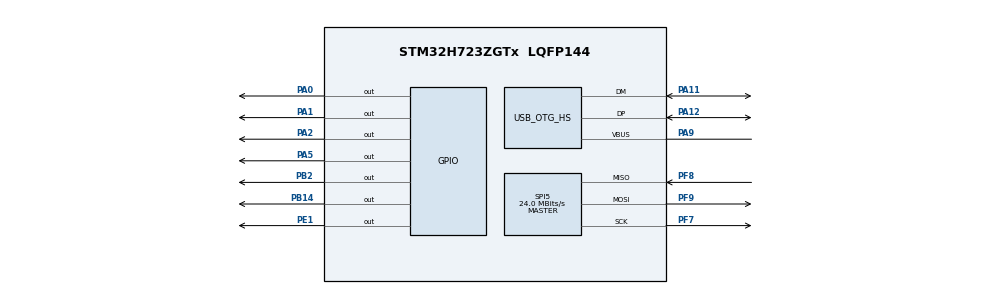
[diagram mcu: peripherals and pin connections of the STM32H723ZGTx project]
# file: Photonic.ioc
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CORTEX_M7.default_mode_Activation=1
Mcu.Family=STM32H7
Mcu.Name=STM32H723ZGTx
Mcu.Package=LQFP144
NVIC.OTG_HS_IRQn=true\:0\:0\:false\:false\:true\:true\:true\:true
NVIC.PriorityGroup=NVIC_PRIORITYGROUP_4
PA0.Signal=GPIO_Output
PA1.Signal=GPIO_Output
PA11.Mode=Device_Only_FS
PA11.Signal=USB_OTG_HS_DM
PA12.Mode=Device_Only_FS
PA12.Signal=USB_OTG_HS_DP
PA13(JTMS/SWDIO).Mode=Serial_Wire
PA13(JTMS/SWDIO).Signal=DEBUG_JTMS-SWDIO
PA14(JTCK/SWCLK).Mode=Serial_Wire
PA14(JTCK/SWCLK).Signal=DEBUG_JTCK-SWCLK
PA2.Signal=GPIO_Output
PA5.Signal=GPIO_Output
PA9.Mode=Activate_VBUS_FS
PA9.Signal=USB_OTG_HS_VBUS
PB14.Signal=GPIO_Output
PB2.Signal=GPIO_Output
PE1.Signal=GPIO_Output
PF7.Mode=Full_Duplex_Master
PF7.Signal=SPI5_SCK
PF8.Mode=Full_Duplex_Master
PF8.Signal=SPI5_MISO
PF9.Mode=Full_Duplex_Master
PF9.Signal=SPI5_MOSI
PH0-OSC_IN.Mode=HSE-External-Clock-Source
PH0-OSC_IN.Signal=RCC_OSC_IN
ProjectManager.HeapSize=0x200
ProjectManager.StackSize=0x400
ProjectManager.TargetToolchain=STM32CubeIDE
RCC.ADCFreq_Value=120000000
RCC.APB1Freq_Value=48000000
RCC.APB2Freq_Value=48000000
RCC.APB3Freq_Value=48000000
RCC.APB4Freq_Value=48000000
RCC.CortexFreq_Value=48000000
RCC.DIVM1=5
RCC.DIVN1=34
RCC.DIVN2=120
RCC.DIVN3=140
RCC.DIVP1=1
RCC.DIVQ1=8
RCC.DIVQ2=3
RCC.DIVQ3=1
RCC.HCLKFreq_Value=48000000
RCC.HSE_VALUE=48000000
RCC.PLLFRACN=3072
RCC.PWR_Regulator_Voltage_Scale=PWR_REGULATOR_VOLTAGE_SCALE3
RCC.SYSCLKFreq_VALUE=48000000
RCC.SYSCLKSource=RCC_SYSCLKSOURCE_HSE
RCC.Spi45ClockSelection=RCC_SPI45CLKSOURCE_HSE
RCC.USBCLockSelection=RCC_USBCLKSOURCE_HSI48
RCC.USBFreq_Value=48000000
SPI5.CLKPhase=SPI_PHASE_2EDGE
SPI5.CalculateBaudRate=24.0 MBits/s
SPI5.DataSize=SPI_DATASIZE_8BIT
SPI5.Direction=SPI_DIRECTION_2LINES
SPI5.Mode=SPI_MODE_MASTER
SPI5.VirtualType=VM_MASTER
TIM1.Prescaler=137
USB_DEVICE.CLASS_NAME_HS=CDC
USB_DEVICE.VirtualMode=Cdc
USB_DEVICE.VirtualModeHS=Cdc_HS
USB_OTG_HS.VirtualMode-Device_Only_FS=Device_Only_FS
VP_MEMORYMAP_VS_MEMORYMAP.Mode=CurAppReg
VP_TIM1_VS_ClockSourceINT.Mode=Internal
VP_USB_DEVICE_VS_USB_DEVICE_CDC_HS.Mode=CDC_HS
board=custom

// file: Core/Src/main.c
/* USER CODE BEGIN Header */
/**
  ******************************************************************************
  * @file           : main.c
  * @brief          : Main program body
  ******************************************************************************
  * @attention
  *
  * Copyright (c) 2025 STMicroelectronics.
  * All rights reserved.
  *
  * This software is licensed under terms that can be found in the LICENSE file
  * in the root directory of this software component.
  * If no LICENSE file comes with this software, it is provided AS-IS.
  *
  ******************************************************************************
  */
/* USER CODE END Header */
#include "main.h"
#include "usb_device.h"

/* USER CODE BEGIN PTD */
#define channel_0 8
/* USER CODE END PTD */

SPI_HandleTypeDef hspi5;

TIM_HandleTypeDef htim1;

void SystemClock_Config(void);
static void MPU_Config(void);
static void MX_GPIO_Init(void);
static void MX_SPI5_Init(void);
static void MX_TIM1_Init(void);
/* USER CODE BEGIN PFP */
uint8_t test;
/* USER CODE END PFP */

int main(void)
{

  /* MPU Configuration--------------------------------------------------------*/
  MPU_Config();

  /* MCU Configuration--------------------------------------------------------*/

  /* Reset of all peripherals, Initializes the Flash interface and the Systick. */
  HAL_Init();

  /* Configure the system clock */
  SystemClock_Config();

  /* Initialize all configured peripherals */
  MX_GPIO_Init();
  MX_SPI5_Init();
  MX_TIM1_Init();
  MX_USB_DEVICE_Init();
  /* USER CODE BEGIN 2 */
  spi_init_24bit();

  /* USER CODE END 2 */

  /* Infinite loop */
  /* USER CODE BEGIN WHILE */
 // HAL_TIM_Base_Start(&htim1); // Start TIM1

  // Read the actual PWR register to see current VOS mode

//uint32_t voltage_uv = 4563123;

//uint16_t voltage_dac = 0xFFFF;

//write_to_dac(3, 10, voltage_dac);
//uint16_t voltage_read = read_dac(3, 10);

//write_to_dac(3, 9, 0x8F32);
//uint16_t voltage_read_0 = read_dac(3, 9);
  //uint8_t voltage[3] = {0x0, 0x01, 0x00};

  GPIOA->BSRR = GPIO_PIN_0;          // set high
  GPIOA->BSRR = GPIO_PIN_1;          // set high
  GPIOA->BSRR = GPIO_PIN_2;          // set high

/*
  uint8_t ref[3] = {0x03, 0x01, 0x00};
  GPIOA->BSRR = GPIO_PIN_0 << 16U;   // set low

  HAL_SPI_Transmit(&hspi5, ref, 3, HAL_MAX_DELAY);
  GPIOA->BSRR = GPIO_PIN_0;

  GPIOA->BSRR = GPIO_PIN_1 << 16U;   // set low

  HAL_SPI_Transmit(&hspi5, ref, 3, HAL_MAX_DELAY);
  GPIOA->BSRR = GPIO_PIN_1;

  GPIOA->BSRR = GPIO_PIN_2 << 16U;   // set low

  HAL_SPI_Transmit(&hspi5, ref, 3, HAL_MAX_DELAY);
  GPIOA->BSRR = GPIO_PIN_2;

  uint8_t config_read[3] = {0x83, 0x00, 0x00};  // 0x83 = read CONFIG (address 0011)
  uint8_t rx[3] = {0};

  GPIOA->BSRR = GPIO_PIN_0 << 16U;   // CS low
  HAL_SPI_TransmitReceive(&hspi5, config_read, rx, 3, HAL_MAX_DELAY);
  GPIOA->BSRR = GPIO_PIN_0;           // CS high
*/
//fillTestValues();
//test = 2;
//__HAL_TIM_SET_COUNTER(&htim1, 0); // Reset counter//z
//fillTestValues();

//write_all_dacs();

//uint32_t elapsed = __HAL_TIM_GET_COUNTER(&htim1); // Read elapsed time

//HAL_TIM_Base_Stop(&htim1); // Stop timer

 // You can now view 'elapsed' in debugger
//read_all_dacs();

//GPIO_PinState state = HAL_GPIO_ReadPin(GPIOA, GPIO_PIN_9);

//test_dacs();

  while (1)
  {
    /* USER CODE END WHILE */

    /* USER CODE BEGIN 3 */
	  GPIOB->BSRR = GPIO_PIN_2;
	  HAL_Delay(2000);

	  GPIOB->BSRR = (uint32_t)GPIO_PIN_2 << 16U;
	  HAL_Delay(2000);

  }
  /* USER CODE END 3 */
}

void SystemClock_Config(void)
{
  RCC_OscInitTypeDef RCC_OscInitStruct = {0};
  RCC_ClkInitTypeDef RCC_ClkInitStruct = {0};

  /** Supply configuration update enable
  */
  HAL_PWREx_ConfigSupply(PWR_LDO_SUPPLY);

  /** Configure the main internal regulator output voltage
  */
  __HAL_PWR_VOLTAGESCALING_CONFIG(PWR_REGULATOR_VOLTAGE_SCALE3);

  while(!__HAL_PWR_GET_FLAG(PWR_FLAG_VOSRDY)) {}

  /** Initializes the RCC Oscillators according to the specified parameters
  * in the RCC_OscInitTypeDef structure.
  */
  RCC_OscInitStruct.OscillatorType = RCC_OSCILLATORTYPE_HSI48|RCC_OSCILLATORTYPE_HSE;
  RCC_OscInitStruct.HSEState = RCC_HSE_BYPASS;
  RCC_OscInitStruct.HSI48State = RCC_HSI48_ON;
  RCC_OscInitStruct.PLL.PLLState = RCC_PLL_NONE;
  if (HAL_RCC_OscConfig(&RCC_OscInitStruct) != HAL_OK)
  {
    Error_Handler();
  }

  /** Initializes the CPU, AHB and APB buses clocks
  */
  RCC_ClkInitStruct.ClockType = RCC_CLOCKTYPE_HCLK|RCC_CLOCKTYPE_SYSCLK
                              |RCC_CLOCKTYPE_PCLK1|RCC_CLOCKTYPE_PCLK2
                              |RCC_CLOCKTYPE_D3PCLK1|RCC_CLOCKTYPE_D1PCLK1;
  RCC_ClkInitStruct.SYSCLKSource = RCC_SYSCLKSOURCE_HSE;
  RCC_ClkInitStruct.SYSCLKDivider = RCC_SYSCLK_DIV1;
  RCC_ClkInitStruct.AHBCLKDivider = RCC_HCLK_DIV1;
  RCC_ClkInitStruct.APB3CLKDivider = RCC_APB3_DIV1;
  RCC_ClkInitStruct.APB1CLKDivider = RCC_APB1_DIV1;
  RCC_ClkInitStruct.APB2CLKDivider = RCC_APB2_DIV1;
  RCC_ClkInitStruct.APB4CLKDivider = RCC_APB4_DIV1;

  if (HAL_RCC_ClockConfig(&RCC_ClkInitStruct, FLASH_LATENCY_1) != HAL_OK)
  {
    Error_Handler();
  }
}

static void MX_SPI5_Init(void)
{

  /* SPI5 parameter configuration*/
  hspi5.Instance = SPI5;
  hspi5.Init.Mode = SPI_MODE_MASTER;
  hspi5.Init.Direction = SPI_DIRECTION_2LINES;
  hspi5.Init.DataSize = SPI_DATASIZE_8BIT;
  hspi5.Init.CLKPolarity = SPI_POLARITY_LOW;
  hspi5.Init.CLKPhase = SPI_PHASE_2EDGE;
  hspi5.Init.NSS = SPI_NSS_SOFT;
  hspi5.Init.BaudRatePrescaler = SPI_BAUDRATEPRESCALER_2;
  hspi5.Init.FirstBit = SPI_FIRSTBIT_MSB;
  hspi5.Init.TIMode = SPI_TIMODE_DISABLE;
  hspi5.Init.CRCCalculation = SPI_CRCCALCULATION_DISABLE;
  hspi5.Init.CRCPolynomial = 0x0;
  hspi5.Init.NSSPMode = SPI_NSS_PULSE_ENABLE;
  hspi5.Init.NSSPolarity = SPI_NSS_POLARITY_LOW;
  hspi5.Init.FifoThreshold = SPI_FIFO_THRESHOLD_01DATA;
  hspi5.Init.TxCRCInitializationPattern = SPI_CRC_INITIALIZATION_ALL_ZERO_PATTERN;
  hspi5.Init.RxCRCInitializationPattern = SPI_CRC_INITIALIZATION_ALL_ZERO_PATTERN;
  hspi5.Init.MasterSSIdleness = SPI_MASTER_SS_IDLENESS_00CYCLE;
  hspi5.Init.MasterInterDataIdleness = SPI_MASTER_INTERDATA_IDLENESS_00CYCLE;
  hspi5.Init.MasterReceiverAutoSusp = SPI_MASTER_RX_AUTOSUSP_DISABLE;
  hspi5.Init.MasterKeepIOState = SPI_MASTER_KEEP_IO_STATE_DISABLE;
  hspi5.Init.IOSwap = SPI_IO_SWAP_DISABLE;
  if (HAL_SPI_Init(&hspi5) != HAL_OK)
  {
    Error_Handler();
  }

}

static void MX_TIM1_Init(void)
{

  TIM_ClockConfigTypeDef sClockSourceConfig = {0};
  TIM_MasterConfigTypeDef sMasterConfig = {0};

  htim1.Instance = TIM1;
  htim1.Init.Prescaler = 137;
  htim1.Init.CounterMode = TIM_COUNTERMODE_UP;
  htim1.Init.Period = 65535;
  htim1.Init.ClockDivision = TIM_CLOCKDIVISION_DIV1;
  htim1.Init.RepetitionCounter = 0;
  htim1.Init.AutoReloadPreload = TIM_AUTORELOAD_PRELOAD_DISABLE;
  if (HAL_TIM_Base_Init(&htim1) != HAL_OK)
  {
    Error_Handler();
  }
  sClockSourceConfig.ClockSource = TIM_CLOCKSOURCE_INTERNAL;
  if (HAL_TIM_ConfigClockSource(&htim1, &sClockSourceConfig) != HAL_OK)
  {
    Error_Handler();
  }
  sMasterConfig.MasterOutputTrigger = TIM_TRGO_RESET;
  sMasterConfig.MasterOutputTrigger2 = TIM_TRGO2_RESET;
  sMasterConfig.MasterSlaveMode = TIM_MASTERSLAVEMODE_DISABLE;
  if (HAL_TIMEx_MasterConfigSynchronization(&htim1, &sMasterConfig) != HAL_OK)
  {
    Error_Handler();
  }

}

static void MX_GPIO_Init(void)
{
  GPIO_InitTypeDef GPIO_InitStruct = {0};

  /* GPIO Ports Clock Enable */
  __HAL_RCC_GPIOF_CLK_ENABLE();
  __HAL_RCC_GPIOH_CLK_ENABLE();
  __HAL_RCC_GPIOA_CLK_ENABLE();
  __HAL_RCC_GPIOB_CLK_ENABLE();
  __HAL_RCC_GPIOE_CLK_ENABLE();

  /*Configure GPIO pin Output Level */
  HAL_GPIO_WritePin(GPIOA, GPIO_PIN_0|GPIO_PIN_1|GPIO_PIN_2|GPIO_PIN_5, GPIO_PIN_RESET);

  /*Configure GPIO pin Output Level */
  HAL_GPIO_WritePin(GPIOB, GPIO_PIN_2|GPIO_PIN_14, GPIO_PIN_RESET);

  /*Configure GPIO pin Output Level */
  HAL_GPIO_WritePin(GPIOE, GPIO_PIN_1, GPIO_PIN_RESET);

  /*Configure GPIO pins : PA0 PA1 PA2 PA5 */
  GPIO_InitStruct.Pin = GPIO_PIN_0|GPIO_PIN_1|GPIO_PIN_2|GPIO_PIN_5;
  GPIO_InitStruct.Mode = GPIO_MODE_OUTPUT_PP;
  GPIO_InitStruct.Pull = GPIO_NOPULL;
  GPIO_InitStruct.Speed = GPIO_SPEED_FREQ_LOW;
  HAL_GPIO_Init(GPIOA, &GPIO_InitStruct);

  /*Configure GPIO pins : PB2 PB14 */
  GPIO_InitStruct.Pin = GPIO_PIN_2|GPIO_PIN_14;
  GPIO_InitStruct.Mode = GPIO_MODE_OUTPUT_PP;
  GPIO_InitStruct.Pull = GPIO_NOPULL;
  GPIO_InitStruct.Speed = GPIO_SPEED_FREQ_LOW;
  HAL_GPIO_Init(GPIOB, &GPIO_InitStruct);

  /*Configure GPIO pin : PE1 */
  GPIO_InitStruct.Pin = GPIO_PIN_1;
  GPIO_InitStruct.Mode = GPIO_MODE_OUTPUT_PP;
  GPIO_InitStruct.Pull = GPIO_NOPULL;
  GPIO_InitStruct.Speed = GPIO_SPEED_FREQ_LOW;
  HAL_GPIO_Init(GPIOE, &GPIO_InitStruct);

  /*AnalogSwitch Config */
  HAL_SYSCFG_AnalogSwitchConfig(SYSCFG_SWITCH_PA0, SYSCFG_SWITCH_PA0_CLOSE);

  /*AnalogSwitch Config */
  HAL_SYSCFG_AnalogSwitchConfig(SYSCFG_SWITCH_PA1, SYSCFG_SWITCH_PA1_CLOSE);

}

 /* MPU Configuration */

void MPU_Config(void)
{
  MPU_Region_InitTypeDef MPU_InitStruct = {0};

  /* Disables the MPU */
  HAL_MPU_Disable();

  /** Initializes and configures the Region and the memory to be protected
  */
  MPU_InitStruct.Enable = MPU_REGION_ENABLE;
  MPU_InitStruct.Number = MPU_REGION_NUMBER0;
  MPU_InitStruct.BaseAddress = 0x0;
  MPU_InitStruct.Size = MPU_REGION_SIZE_4GB;
  MPU_InitStruct.SubRegionDisable = 0x87;
  MPU_InitStruct.TypeExtField = MPU_TEX_LEVEL0;
  MPU_InitStruct.AccessPermission = MPU_REGION_NO_ACCESS;
  MPU_InitStruct.DisableExec = MPU_INSTRUCTION_ACCESS_DISABLE;
  MPU_InitStruct.IsShareable = MPU_ACCESS_SHAREABLE;
  MPU_InitStruct.IsCacheable = MPU_ACCESS_NOT_CACHEABLE;
  MPU_InitStruct.IsBufferable = MPU_ACCESS_NOT_BUFFERABLE;

  HAL_MPU_ConfigRegion(&MPU_InitStruct);
  /* Enables the MPU */
  HAL_MPU_Enable(MPU_PRIVILEGED_DEFAULT);

}

void Error_Handler(void)
{
  __disable_irq();
  while (1)
  {
  }
}
